# LPC12D27 register map
File version: 3
Registers are 32-bit, read-write, reset 0x0 unless marked. A register's access mark holds for its fields unless they carry their own. Offsets are from the block's base; [hi:lo] are bit positions; {n}, {i} and the like mark numbered series; 'fields as' and 'values as' point back to an identical list.

## I2C — Product name title=UM10441 Chapter title=LPC122x I2C-bus controller Modification date=2/2/2011 Major revision=0 Minor revision=17
Base 0x40000000
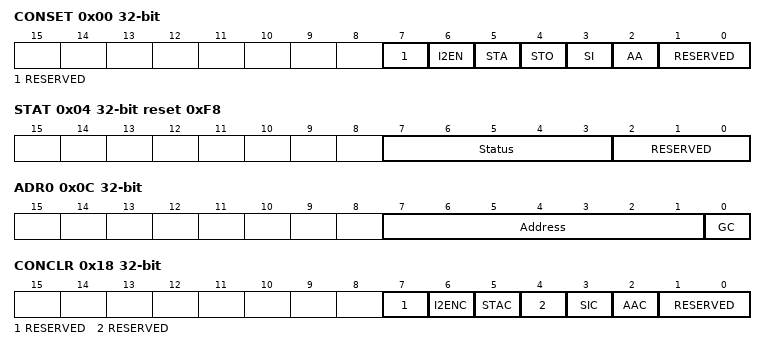
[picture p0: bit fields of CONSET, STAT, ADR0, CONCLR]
0x00 CONSET — I2C Control Set Register. When a one is written to a bit of this register, the corresponding bit in the I2C control register is set. Writing a zero has no effect on the corresponding bit in the I2C control register.
  [7] RESERVED — Reserved. User software should not write ones to reserved bits. The value read from a reserved bit is not defined.
  [6] I2EN — I2C interface enable.
  [5] STA — START flag.
  [4] STO — STOP flag.
  [3] SI — I2C interrupt flag.
  [2] AA — Assert acknowledge flag.
  [1:0] RESERVED — Reserved. User software should not write ones to reserved bits. The value read from a reserved bit is not defined.
0x04 STAT ro reset 0xF8 — I2C Status Register. During I2C operation, this register provides detailed status codes that allow software to determine the next action needed.
  [7:3] Status — These bits give the actual status information about the I2C interface.
  [2:0] RESERVED — These bits are unused and are always 0.
0x08 DAT — I2C Data Register. During master or slave transmit mode, data to be transmitted is written to this register. During master or slave receive mode, data that has been received may be read from this register.
  [7:0] Data — This register holds data values that have been received or are to be transmitted.
0x0C ADR0 — I2C Slave Address Register 0. Contains the 7-bit slave address for operation of the I2C interface in slave mode, and is not used in master mode. The least significant bit determines whether a slave responds to the General Call address.
  [7:1] Address — The I2C device address for slave mode.
  [0] GC — General Call enable bit.
0x10 SCLH reset 0x4 — SCH Duty Cycle Register High Half Word. Determines the high time of the I2C clock.
  [15:0] SCLH — Count for SCL HIGH time period selection.
0x14 SCLL reset 0x4 — SCL Duty Cycle Register Low Half Word. Determines the low time of the I2C clock. I2nSCLL and I2nSCLH together determine the clock frequency generated by an I2C master and certain times used in slave mode.
  [15:0] SCLL — Count for SCL low time period selection.
0x18 CONCLR wo — I2C Control Clear Register. When a one is written to a bit of this register, the corresponding bit in the I2C control register is cleared. Writing a zero has no effect on the corresponding bit in the I2C control register.
  [7] RESERVED — Reserved. User software should not write ones to reserved bits. The value read from a reserved bit is not defined.
  [6] I2ENC — I2C interface Disable bit.
  [5] STAC — START flag Clear bit.
  [4] RESERVED — Reserved. User software should not write ones to reserved bits. The value read from a reserved bit is not defined.
  [3] SIC — I2C interrupt Clear bit.
  [2] AAC — Assert acknowledge Clear bit.
  [1:0] RESERVED — Reserved. User software should not write ones to reserved bits. The value read from a reserved bit is not defined.
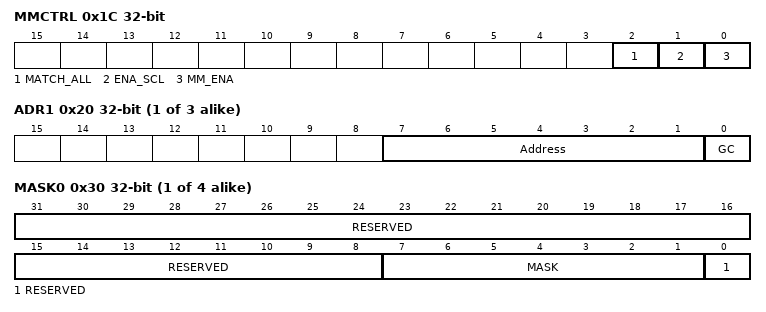
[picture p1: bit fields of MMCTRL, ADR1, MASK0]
0x1C MMCTRL — Monitor mode control register.
  [2] MATCH_ALL — Select interrupt register match.
    0=WHEN_THIS_BIT_IS_CLE (When this bit is cleared, an interrupt will only be generated when a match occurs to one of the (up-to) four address registers described above. That is, the module will respond as a normal slave as far as address-recognition is concerned.); 1=WHEN_THIS_BIT_IS_SET (When this bit is set to 1 and the I2C is in monitor mode, an interrupt will be generated on ANY address received. This will enable the part to monitor all traffic on the bus.)
  [1] ENA_SCL — SCL output enable.
    0=WHEN_THIS_BIT_IS_CLE (When this bit is cleared to 0, the SCL output will be forced high when the module is in monitor mode. As described above, this will prevent the module from having any control over the I2C clock line.); 1=WHEN_THIS_BIT_IS_SET (When this bit is set, the I2C module may exercise the same control over the clock line that it would in normal operation. This means that, acting as a slave peripheral, the I2C module can stretch the clock line (hold it low) until it has had time to respond to an I 2C interrupt. When the ENA_SCL bit is cleared and the I2C no longer has the ability to stall the bus, interrupt response time becomes important. To give the part more time to respond to an I2C interrupt under these conditions, a DATA _BUFFER register is used to hold received data for a full 9-bit word transmission time.)
  [0] MM_ENA — Monitor mode enable.
    0=MONITOR_MODE_DISABLE (Monitor mode disabled.); 1=THE_I2C_MODULE_WILL_ (The I2C module will enter monitor mode. In this mode the SDA output will be forced high. This will prevent the I2C module from outputting data of any kind (including ACK) onto the I2C data bus. Depending on the state of the ENA_SCL bit, the output may be also forced high, preventing the module from having control over the I2C clock line.)
{0x1C+4i} ADR{i} (i=1..3) — I2C Slave Address Register. Contains the 7-bit slave address for operation of the I2C interface in slave mode, and is not used in master mode. The least significant bit determines whether a slave responds to the General Call address.
  fields as ADR0
0x2C DATA_BUFFER ro — Data buffer register. The contents of the 8 MSBs of the I2DAT shift register will be transferred to the DATA_BUFFER automatically after every nine bits (8 bits of data plus ACK or NACK) has been received on the bus.
  [7:0] Data — This register holds contents of the 8 MSBs of the I2DAT shift register.
{0x30+4i} MASK{i} (i=0..3) — I2C Slave address mask register. This mask register is associated with I2ADR0 to determine an address match. The mask register has no effect when comparing to the General Call address (0000000).
  [31:8] RESERVED — Reserved. User software should not write ones to reserved bits. These bits read always back as 0s.
  [7:1] MASK — Mask bits.
  [0] RESERVED — Reserved. User software should not write ones to reserved bits. This bit reads always back as 0.
